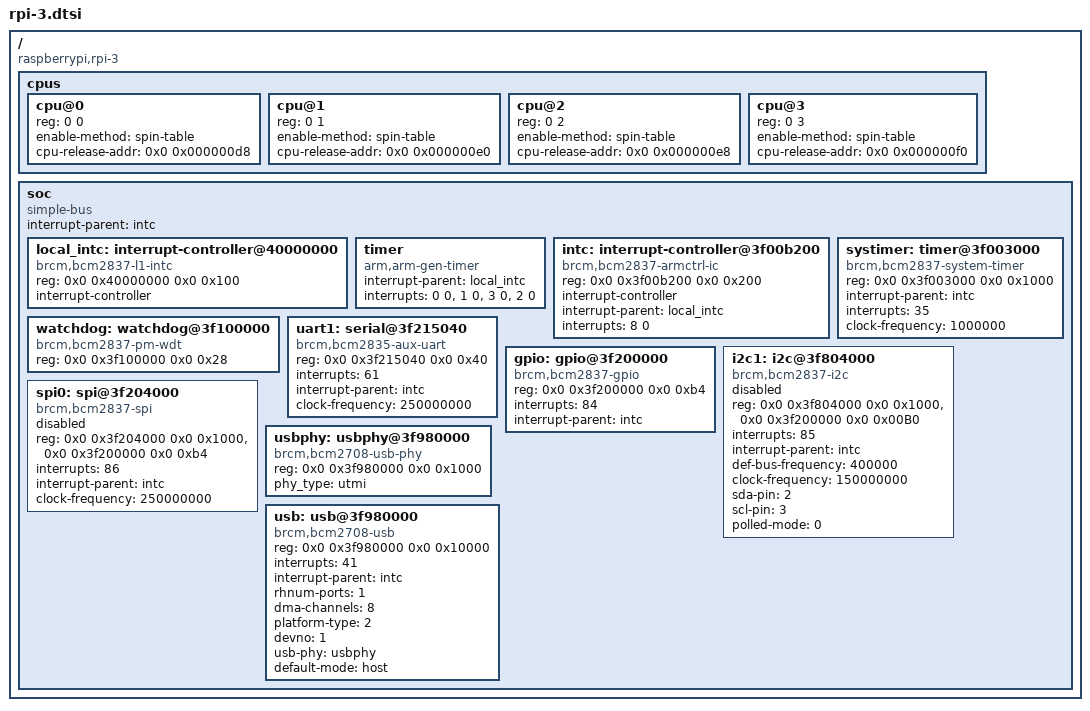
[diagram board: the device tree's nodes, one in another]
/* rpi-3.dtsi - Raspberry Pi 3 processer family device tree source */

/*
modification history
--------------------
20may19,hkl  added USB controller and PHY support (F11409)
08mar19,hkl  created (F11409)
*/

/   {
    compatible = "raspberrypi,rpi-3";

    #address-cells = <2>;
    #size-cells = <2>;

    cpus
        {
        #size-cells = <0>;
        #address-cells = <2>;

        cpu@0
            {
            device_type = "cpu";
            reg = <0 0>;
            enable-method = "spin-table";
            cpu-release-addr = <0x0 0x000000d8>;
            };

        cpu@1
            {
            device_type = "cpu";
            reg = <0 1>;
            enable-method = "spin-table";
            cpu-release-addr = <0x0 0x000000e0>;
            };

        cpu@2
            {
            device_type = "cpu";
            reg = <0 2>;
            enable-method = "spin-table";
            cpu-release-addr = <0x0 0x000000e8>;
            };

        cpu@3
            {
            device_type = "cpu";
            reg = <0 3>;
            enable-method = "spin-table";
            cpu-release-addr = <0x0 0x000000f0>;
            };
        };

    soc: soc
        {
        compatible = "simple-bus";
        device_type = "soc";
        #address-cells = <2>;
        #size-cells = <2>;
        interrupt-parent = <&intc>;

        local_intc: interrupt-controller@40000000
            {
            compatible = "brcm,bcm2837-l1-intc";
            reg = <0x0 0x40000000 0x0 0x100>;
            interrupt-controller;
            #interrupt-cells = <2>;
            };

        timer: timer
            {
            compatible = "arm,arm-gen-timer";
            interrupt-parent = <&local_intc>;
            interrupts = <0 0>, /* Physical Secure */
                         <1 0>, /* Physical Non-Secure */
                         <3 0>, /* Virtual */
                         <2 0>; /* Hypervisor */
            };

        intc: interrupt-controller@3f00b200
            {
            compatible = "brcm,bcm2837-armctrl-ic";
            reg = <0x0 0x3f00b200 0x0 0x200>;
            interrupt-controller;
            #interrupt-cells = <1>;
            interrupt-parent = <&local_intc>;
            interrupts = <8 0>;
            };

        systimer: timer@3f003000
            {
            compatible = "brcm,bcm2837-system-timer";
            reg = <0x0 0x3f003000 0x0 0x1000>;
            interrupt-parent = <&intc>;
            interrupts = <35>;
            clock-frequency = <1000000>;
            };

        watchdog: watchdog@3f100000
            {
            compatible = "brcm,bcm2837-pm-wdt";
            reg = <0x0 0x3f100000 0x0 0x28>;
            };

        uart1: serial@3f215040
            {
            compatible = "brcm,bcm2835-aux-uart";
            reg = <0x0 0x3f215040 0x0 0x40>;
            interrupts = <61>;
            interrupt-parent = <&intc>;
            clock-frequency = <250000000>;
            };

        gpio: gpio@3f200000
            {
            compatible = "brcm,bcm2837-gpio";
            reg = <0x0 0x3f200000 0x0 0xb4>;
            interrupts = <84>;
            interrupt-parent = <&intc>;
            #gpio-cells = <4>;
            };

        i2c1: i2c@3f804000
            {
            compatible = "brcm,bcm2837-i2c";
            reg = <0x0 0x3f804000 0x0 0x1000>,
                  <0x0 0x3f200000 0x0 0x00B0>;
            interrupts = <85>;
            interrupt-parent = <&intc>;
            def-bus-frequency = <400000>;
            clock-frequency = <150000000>;
            sda-pin = <2>;
            scl-pin = <3>;
            #address-cells = <1>;
            #size-cells = <0>;
            polled-mode = <0>;
            status = "disabled";
            };

        spi0: spi@3f204000
            {
            compatible = "brcm,bcm2837-spi";
            #address-cells = <1>;
            #size-cells = <0>;
            reg = <0x0 0x3f204000 0x0 0x1000>,
                  <0x0 0x3f200000 0x0 0xb4>;
            interrupts = <86>;
            interrupt-parent = <&intc>;
            clock-frequency = <250000000>;
            status = "disabled";
            };

        usbphy: usbphy@3f980000
            {
            compatible = "brcm,bcm2708-usb-phy";
            reg = <0x0 0x3f980000 0x0 0x1000>;
            phy_type = "utmi";
            };

        usb: usb@3f980000
            {
            compatible = "brcm,bcm2708-usb";
            reg = <0x0 0x3f980000 0x0 0x10000>;
            interrupts = <41>;
            interrupt-parent = <&intc>;
            rhnum-ports = <1>;
            dma-channels = <8>;
            platform-type = <2>; /* 2: Raspberry Pi 3 */
            devno = <1>;
            usb-phy = <&usbphy>;
            default-mode = "host";
            };
        };
    };
